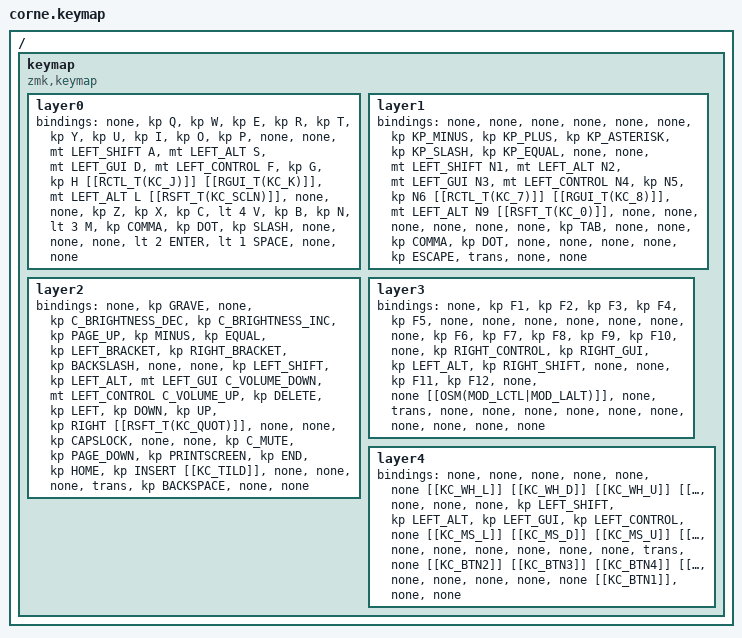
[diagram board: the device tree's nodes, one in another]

  /*
  * Copyright (c) 2020 The ZMK Contributors
  *
  * SPDX-License-Identifier: MIT
  */

  #include <behaviors.dtsi>
  #include <dt-bindings/zmk/keys.h>
  #include <dt-bindings/zmk/bt.h>
  #include <dt-bindings/zmk/ext_power.h>

  / {
    keymap {
      compatible = "zmk,keymap";
  layer0 {
          bindings = <
          &none &kp Q &kp W &kp E &kp R &kp T &kp Y &kp U &kp I &kp O &kp P &none &none &mt LEFT_SHIFT A &mt LEFT_ALT S &mt LEFT_GUI D &mt LEFT_CONTROL F &kp G &kp H [[RCTL_T(KC_J)]] [[RGUI_T(KC_K)]] &mt LEFT_ALT L [[RSFT_T(KC_SCLN)]] &none &none &kp Z &kp X &kp C &lt 4 V &kp B &kp N &lt 3 M &kp COMMA &kp DOT &kp SLASH &none &none &none &lt 2 ENTER &lt 1 SPACE &none &none
          >;
        };layer1 {
          bindings = <
          &none &none &none &none &none &none &kp KP_MINUS &kp KP_PLUS &kp KP_ASTERISK &kp KP_SLASH &kp KP_EQUAL &none &none &mt LEFT_SHIFT N1 &mt LEFT_ALT N2 &mt LEFT_GUI N3 &mt LEFT_CONTROL N4 &kp N5 &kp N6 [[RCTL_T(KC_7)]] [[RGUI_T(KC_8)]] &mt LEFT_ALT N9 [[RSFT_T(KC_0)]] &none &none &none &none &none &none &kp TAB &none &none &kp COMMA &kp DOT &none &none &none &none &kp ESCAPE &trans &none &none
          >;
        };layer2 {
          bindings = <
          &none &kp GRAVE &none &kp C_BRIGHTNESS_DEC &kp C_BRIGHTNESS_INC &kp PAGE_UP &kp MINUS &kp EQUAL &kp LEFT_BRACKET &kp RIGHT_BRACKET &kp BACKSLASH &none &none &kp LEFT_SHIFT &kp LEFT_ALT &mt LEFT_GUI C_VOLUME_DOWN &mt LEFT_CONTROL C_VOLUME_UP &kp DELETE &kp LEFT &kp DOWN &kp UP &kp RIGHT [[RSFT_T(KC_QUOT)]] &none &none &kp CAPSLOCK &none &none &kp C_MUTE &kp PAGE_DOWN &kp PRINTSCREEN &kp END &kp HOME &kp INSERT [[KC_TILD]] &none &none &none &trans &kp BACKSPACE &none &none
          >;
        };layer3 {
          bindings = <
          &none &kp F1 &kp F2 &kp F3 &kp F4 &kp F5 &none &none &none &none &none &none &none &kp F6 &kp F7 &kp F8 &kp F9 &kp F10 &none &kp RIGHT_CONTROL &kp RIGHT_GUI &kp LEFT_ALT &kp RIGHT_SHIFT &none &none &kp F11 &kp F12 &none &none [[OSM(MOD_LCTL|MOD_LALT)]] &none &trans &none &none &none &none &none &none &none &none &none &none
          >;
        };layer4 {
          bindings = <
          &none &none &none &none &none &none [[KC_WH_L]] [[KC_WH_D]] [[KC_WH_U]] [[KC_WH_R]] &none &none &none &kp LEFT_SHIFT &kp LEFT_ALT &kp LEFT_GUI &kp LEFT_CONTROL &none [[KC_MS_L]] [[KC_MS_D]] [[KC_MS_U]] [[KC_MS_R]] &none &none &none &none &none &none &trans &none [[KC_BTN2]] [[KC_BTN3]] [[KC_BTN4]] [[KC_BTN5]] &none &none &none &none &none [[KC_BTN1]] &none &none
          >;
        };
    };
  };
  
